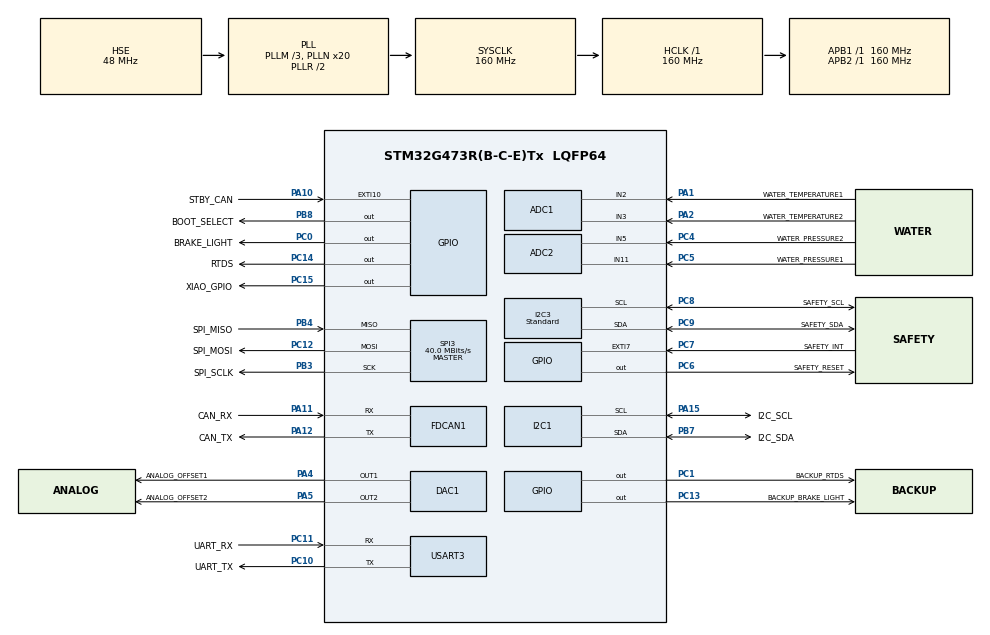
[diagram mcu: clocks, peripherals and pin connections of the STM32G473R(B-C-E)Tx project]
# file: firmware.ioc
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ADC1.Channel-0\#ChannelRegularConversion=ADC_CHANNEL_2
ADC1.Channel-1\#ChannelRegularConversion=ADC_CHANNEL_3
ADC1.Channel-2\#ChannelRegularConversion=ADC_CHANNEL_2
ADC1.Channel-3\#ChannelRegularConversion=ADC_CHANNEL_3
ADC1.Channel-4\#ChannelRegularConversion=ADC_CHANNEL_2
ADC1.Channel-5\#ChannelRegularConversion=ADC_CHANNEL_2
ADC1.ClockPrescaler=ADC_CLOCK_ASYNC_DIV128
ADC1.ContinuousConvMode=ENABLE
ADC1.DMAContinuousRequests=ENABLE
ADC1.EOCSelection=ADC_EOC_SEQ_CONV
ADC1.NbrOfConversion=6
ADC1.NbrOfConversionFlag=1
ADC1.OffsetNumber-0\#ChannelRegularConversion=ADC_OFFSET_NONE
ADC1.OffsetNumber-1\#ChannelRegularConversion=ADC_OFFSET_NONE
ADC1.OffsetNumber-2\#ChannelRegularConversion=ADC_OFFSET_NONE
ADC1.OffsetNumber-3\#ChannelRegularConversion=ADC_OFFSET_NONE
ADC1.OffsetNumber-4\#ChannelRegularConversion=ADC_OFFSET_NONE
ADC1.OffsetNumber-5\#ChannelRegularConversion=ADC_OFFSET_NONE
ADC1.Overrun=ADC_OVR_DATA_OVERWRITTEN
ADC1.Rank-0\#ChannelRegularConversion=1
ADC1.Rank-1\#ChannelRegularConversion=2
ADC1.Rank-2\#ChannelRegularConversion=3
ADC1.Rank-3\#ChannelRegularConversion=4
ADC1.Rank-4\#ChannelRegularConversion=5
ADC1.Rank-5\#ChannelRegularConversion=6
ADC1.SamplingTime-0\#ChannelRegularConversion=ADC_SAMPLETIME_12CYCLES_5
ADC1.SamplingTime-1\#ChannelRegularConversion=ADC_SAMPLETIME_12CYCLES_5
ADC1.SamplingTime-2\#ChannelRegularConversion=ADC_SAMPLETIME_12CYCLES_5
ADC1.SamplingTime-3\#ChannelRegularConversion=ADC_SAMPLETIME_12CYCLES_5
ADC1.SamplingTime-4\#ChannelRegularConversion=ADC_SAMPLETIME_12CYCLES_5
ADC1.SamplingTime-5\#ChannelRegularConversion=ADC_SAMPLETIME_12CYCLES_5
ADC1.master=1
ADC2.Channel-0\#ChannelRegularConversion=ADC_CHANNEL_5
ADC2.Channel-1\#ChannelRegularConversion=ADC_CHANNEL_11
ADC2.Channel-2\#ChannelRegularConversion=ADC_CHANNEL_5
ADC2.Channel-3\#ChannelRegularConversion=ADC_CHANNEL_11
ADC2.ClockPrescaler=ADC_CLOCK_ASYNC_DIV128
ADC2.ContinuousConvMode=ENABLE
ADC2.DMAContinuousRequests=ENABLE
ADC2.EOCSelection=ADC_EOC_SEQ_CONV
ADC2.NbrOfConversion=4
ADC2.NbrOfConversionFlag=1
ADC2.OffsetNumber-0\#ChannelRegularConversion=ADC_OFFSET_NONE
ADC2.OffsetNumber-1\#ChannelRegularConversion=ADC_OFFSET_NONE
ADC2.OffsetNumber-2\#ChannelRegularConversion=ADC_OFFSET_NONE
ADC2.OffsetNumber-3\#ChannelRegularConversion=ADC_OFFSET_NONE
ADC2.Overrun=ADC_OVR_DATA_OVERWRITTEN
ADC2.Rank-0\#ChannelRegularConversion=1
ADC2.Rank-1\#ChannelRegularConversion=2
ADC2.Rank-2\#ChannelRegularConversion=3
ADC2.Rank-3\#ChannelRegularConversion=4
ADC2.SamplingTime-0\#ChannelRegularConversion=ADC_SAMPLETIME_2CYCLES_5
ADC2.SamplingTime-1\#ChannelRegularConversion=ADC_SAMPLETIME_2CYCLES_5
ADC2.SamplingTime-2\#ChannelRegularConversion=ADC_SAMPLETIME_2CYCLES_5
ADC2.SamplingTime-3\#ChannelRegularConversion=ADC_SAMPLETIME_2CYCLES_5
DAC1.DAC_Channel-DAC_OUT2=DAC_CHANNEL_2
Dma.ADC1.0.Direction=DMA_PERIPH_TO_MEMORY
Dma.ADC1.0.EventEnable=DISABLE
Dma.ADC1.0.Instance=DMA1_Channel1
Dma.ADC1.0.MemDataAlignment=DMA_MDATAALIGN_HALFWORD
Dma.ADC1.0.MemInc=DMA_MINC_ENABLE
Dma.ADC1.0.Mode=DMA_CIRCULAR
Dma.ADC1.0.PeriphDataAlignment=DMA_PDATAALIGN_HALFWORD
Dma.ADC1.0.PeriphInc=DMA_PINC_DISABLE
Dma.ADC1.0.Polarity=HAL_DMAMUX_REQ_GEN_RISING
Dma.ADC1.0.Priority=DMA_PRIORITY_LOW
Dma.ADC1.0.RequestNumber=1
Dma.ADC1.0.SignalID=NONE
Dma.ADC1.0.SyncEnable=DISABLE
Dma.ADC1.0.SyncPolarity=HAL_DMAMUX_SYNC_NO_EVENT
Dma.ADC1.0.SyncRequestNumber=1
Dma.ADC1.0.SyncSignalID=NONE
Dma.ADC2.1.Direction=DMA_PERIPH_TO_MEMORY
Dma.ADC2.1.EventEnable=DISABLE
Dma.ADC2.1.Instance=DMA2_Channel2
Dma.ADC2.1.MemDataAlignment=DMA_MDATAALIGN_HALFWORD
Dma.ADC2.1.MemInc=DMA_MINC_ENABLE
Dma.ADC2.1.Mode=DMA_CIRCULAR
Dma.ADC2.1.PeriphDataAlignment=DMA_PDATAALIGN_HALFWORD
Dma.ADC2.1.PeriphInc=DMA_PINC_DISABLE
Dma.ADC2.1.Polarity=HAL_DMAMUX_REQ_GEN_RISING
Dma.ADC2.1.Priority=DMA_PRIORITY_LOW
Dma.ADC2.1.RequestNumber=1
Dma.ADC2.1.SignalID=NONE
Dma.ADC2.1.SyncEnable=DISABLE
Dma.ADC2.1.SyncPolarity=HAL_DMAMUX_SYNC_NO_EVENT
Dma.ADC2.1.SyncRequestNumber=1
Dma.ADC2.1.SyncSignalID=NONE
Dma.Request0=ADC1
Dma.Request1=ADC2
Dma.Request2=USART3_TX
Dma.USART3_TX.2.Direction=DMA_MEMORY_TO_PERIPH
Dma.USART3_TX.2.EventEnable=DISABLE
Dma.USART3_TX.2.Instance=DMA1_Channel2
Dma.USART3_TX.2.MemDataAlignment=DMA_MDATAALIGN_BYTE
Dma.USART3_TX.2.MemInc=DMA_MINC_ENABLE
Dma.USART3_TX.2.Mode=DMA_NORMAL
Dma.USART3_TX.2.PeriphDataAlignment=DMA_PDATAALIGN_BYTE
Dma.USART3_TX.2.PeriphInc=DMA_PINC_DISABLE
Dma.USART3_TX.2.Polarity=HAL_DMAMUX_REQ_GEN_RISING
Dma.USART3_TX.2.Priority=DMA_PRIORITY_LOW
Dma.USART3_TX.2.RequestNumber=1
Dma.USART3_TX.2.SignalID=NONE
Dma.USART3_TX.2.SyncEnable=DISABLE
Dma.USART3_TX.2.SyncPolarity=HAL_DMAMUX_SYNC_NO_EVENT
Dma.USART3_TX.2.SyncRequestNumber=1
Dma.USART3_TX.2.SyncSignalID=NONE
FDCAN1.CalculateBaudRateNominal=1000000
FDCAN1.CalculateTimeBitNominal=1000
FDCAN1.CalculateTimeQuantumNominal=62.5
FDCAN1.DataPrescaler=1
FDCAN1.DataSyncJumpWidth=2
FDCAN1.FrameFormat=FDCAN_FRAME_CLASSIC
FDCAN1.NominalPrescaler=10
FDCAN1.NominalSyncJumpWidth=2
FDCAN1.NominalTimeSeg1=13
FDCAN1.NominalTimeSeg2=2
FDCAN1.StdFiltersNbr=1
FREERTOS.Mutexes01=dataMutex,Dynamic,NULL;safetyMutex,Dynamic,NULL
FREERTOS.Tasks01=defaultTask,24,128,Default_Task,Default,NULL,Dynamic,NULL,NULL;interfaceTask,24,256,Interface_Task,As external,NULL,Dynamic,NULL,NULL;communicationTask,24,256,Communication_Task,As external,NULL,Dynamic,NULL,NULL;safetyTask,32,256,Safety_Task,As external,NULL,Dynamic,NULL,NULL;ledTestTask,8,128,Led_Test_Task,As external,NULL,Dynamic,NULL,NULL
FREERTOS.configMAX_TASK_NAME_LEN=24
FREERTOS.configTOTAL_HEAP_SIZE=16384
FREERTOS.configUSE_NEWLIB_REENTRANT=1
I2C1.Timing=0x30D29DE4
I2C3.I2C_Fall_Time=300
I2C3.I2C_Rise_Time=1000
I2C3.I2C_Speed_Mode=I2C_Standard
I2C3.Timing=0xD0E32C34
Mcu.Family=STM32G4
Mcu.Name=STM32G473R(B-C-E)Tx
Mcu.Package=LQFP64
NVIC.DMA1_Channel1_IRQn=true\:5\:0\:true\:false\:true\:true\:false\:true\:true
NVIC.DMA1_Channel2_IRQn=true\:5\:0\:false\:false\:true\:true\:false\:true\:true
NVIC.DMA2_Channel2_IRQn=true\:5\:0\:true\:false\:true\:true\:false\:true\:true
NVIC.FDCAN1_IT0_IRQn=true\:5\:0\:false\:false\:true\:true\:true\:true\:true
NVIC.FDCAN1_IT1_IRQn=true\:5\:0\:false\:false\:true\:true\:true\:true\:true
NVIC.PriorityGroup=NVIC_PRIORITYGROUP_4
NVIC.TIM6_DAC_IRQn=true\:15\:0\:false\:false\:true\:false\:false\:true\:true
NVIC.TimeBase=TIM6_DAC_IRQn
NVIC.TimeBaseIP=TIM6
PA1.GPIO_Label=WATER_TEMPERATURE1
PA1.GPIO_Mode=GPIO_MODE_ANALOG
PA1.Mode=IN2-Single-Ended
PA1.Signal=ADC1_IN2
PA10.GPIO_Label=STBY_CAN
PA10.Signal=GPXTI10
PA11.GPIO_Label=CAN_RX
PA11.Mode=FDCAN_Activate
PA11.Signal=FDCAN1_RX
PA12.GPIO_Label=CAN_TX
PA12.Mode=FDCAN_Activate
PA12.Signal=FDCAN1_TX
PA13.GPIO_Label=SWDIO
PA13.Mode=Serial_Wire
PA13.Signal=SYS_JTMS-SWDIO
PA14.GPIO_Label=SWCLK
PA14.Mode=Serial_Wire
PA14.Signal=SYS_JTCK-SWCLK
PA15.GPIO_Label=I2C_SCL
PA15.Mode=I2C
PA15.Signal=I2C1_SCL
PA2.GPIO_Label=WATER_TEMPERATURE2
PA2.Mode=IN3-Single-Ended
PA2.Signal=ADC1_IN3
PA4.GPIO_Label=ANALOG_OFFSET1
PA4.Signal=COMP_DAC11_group
PA5.GPIO_Label=ANALOG_OFFSET2
PA5.Signal=COMP_DAC12_group
PB3.GPIO_Label=SPI_SCLK
PB3.Mode=Full_Duplex_Master
PB3.Signal=SPI3_SCK
PB4.GPIO_Label=SPI_MISO
PB4.Mode=Full_Duplex_Master
PB4.Signal=SPI3_MISO
PB7.GPIO_Label=I2C_SDA
PB7.Mode=I2C
PB7.Signal=I2C1_SDA
PB8-BOOT0.GPIO_Label=BOOT_SELECT
PB8-BOOT0.Signal=GPIO_Output
PC0.GPIO_Label=BRAKE_LIGHT
PC0.Signal=GPIO_Output
PC1.GPIO_Label=BACKUP_RTDS
PC1.Signal=GPIO_Output
PC10.GPIO_Label=UART_TX
PC10.Mode=Asynchronous
PC10.Signal=USART3_TX
PC11.GPIO_Label=UART_RX
PC11.Mode=Asynchronous
PC11.Signal=USART3_RX
PC12.GPIO_Label=SPI_MOSI
PC12.Mode=Full_Duplex_Master
PC12.Signal=SPI3_MOSI
PC13.GPIO_Label=BACKUP_BRAKE_LIGHT
PC13.Signal=GPIO_Output
PC14-OSC32_IN.GPIO_Label=RTDS
PC14-OSC32_IN.Signal=GPIO_Output
PC15-OSC32_OUT.GPIO_Label=XIAO_GPIO
PC15-OSC32_OUT.Signal=GPIO_Output
PC4.GPIO_Label=WATER_PRESSURE2
PC4.Mode=IN5-Single-Ended
PC4.Signal=ADC2_IN5
PC5.GPIO_Label=WATER_PRESSURE1
PC5.Mode=IN11-Single-Ended
PC5.Signal=ADC2_IN11
PC6.GPIO_Label=SAFETY_RESET
PC6.GPIO_PuPd=GPIO_PULLUP
PC6.PinState=GPIO_PIN_SET
PC6.Signal=GPIO_Output
PC7.GPIO_Label=SAFETY_INT
PC7.GPIO_ModeDefaultEXTI=GPIO_MODE_IT_FALLING
PC7.GPIO_PuPd=GPIO_PULLUP
PC7.Signal=GPXTI7
PC8.GPIO_Label=SAFETY_SCL
PC8.GPIO_Pu=GPIO_PULLUP
PC8.Mode=I2C
PC8.Signal=I2C3_SCL
PC9.GPIO_Label=SAFETY_SDA
PC9.GPIO_Pu=GPIO_PULLUP
PC9.Mode=I2C
PC9.Signal=I2C3_SDA
PF0-OSC_IN.GPIO_Label=HSE_IN
PF0-OSC_IN.Mode=HSE-External-Oscillator
PF0-OSC_IN.Signal=RCC_OSC_IN
PF1-OSC_OUT.GPIO_Label=HSE_OUT
PF1-OSC_OUT.Mode=HSE-External-Oscillator
PF1-OSC_OUT.Signal=RCC_OSC_OUT
ProjectManager.HeapSize=0x200
ProjectManager.StackSize=0x400
ProjectManager.TargetToolchain=CMake
RCC.ADC12Freq_Value=160000000
RCC.ADC345Freq_Value=160000000
RCC.AHBFreq_Value=160000000
RCC.APB1Freq_Value=160000000
RCC.APB1TimFreq_Value=160000000
RCC.APB2Freq_Value=160000000
RCC.APB2TimFreq_Value=160000000
RCC.CK48CLockSelection=RCC_USBCLKSOURCE_HSI48
RCC.CortexFreq_Value=160000000
RCC.EXTERNAL_CLOCK_VALUE=12288000
RCC.HCLKFreq_Value=160000000
RCC.HSE_VALUE=48000000
RCC.HSI48_VALUE=48000000
RCC.HSI_VALUE=16000000
RCC.LSE_VALUE=32768
RCC.PLLM=RCC_PLLM_DIV3
RCC.PLLN=20
RCC.PLLQ=RCC_PLLQ_DIV8
RCC.PLLSourceVirtual=RCC_PLLSOURCE_HSE
RCC.SYSCLKFreq_VALUE=160000000
RCC.SYSCLKSource=RCC_SYSCLKSOURCE_PLLCLK
RCC.USBFreq_Value=48000000
RCC.VCOOutputFreq_Value=320000000
SH.COMP_DAC11_group.0=DAC1_OUT1,DAC_OUT1
SH.COMP_DAC12_group.0=DAC1_OUT2,DAC_OUT2
SPI3.BaudRatePrescaler=SPI_BAUDRATEPRESCALER_4
SPI3.CalculateBaudRate=40.0 MBits/s
SPI3.Direction=SPI_DIRECTION_2LINES
SPI3.Mode=SPI_MODE_MASTER
SPI3.VirtualType=VM_MASTER
USART3.SwapParam=ADVFEATURE_SWAP_ENABLE
USART3.VirtualMode-Asynchronous=VM_ASYNC
VP_FREERTOS_VS_CMSIS_V2.Mode=CMSIS_V2
VP_SYS_VS_DBSignals.Mode=DisableDeadBatterySignals
VP_SYS_VS_tim6.Mode=TIM6
board=custom

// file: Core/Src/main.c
/* USER CODE BEGIN Header */
/**
  ******************************************************************************
  * @file           : main.c
  * @brief          : Main program body
  ******************************************************************************
  * @attention
  *
  * Copyright (c) 2026 STMicroelectronics.
  * All rights reserved.
  *
  * This software is licensed under terms that can be found in the LICENSE file
  * in the root directory of this software component.
  * If no LICENSE file comes with this software, it is provided AS-IS.
  *
  ******************************************************************************
  */
/* USER CODE END Header */
#include "main.h"
#include "cmsis_os.h"
#include "adc.h"
#include "dac.h"
#include "dma.h"
#include "fdcan.h"
#include "i2c.h"
#include "spi.h"
#include "usart.h"
#include "gpio.h"

void SystemClock_Config(void);
void MX_FREERTOS_Init(void);

int main(void)
{

  /* MCU Configuration--------------------------------------------------------*/

  /* Reset of all peripherals, Initializes the Flash interface and the Systick. */
  HAL_Init();

  /* Configure the system clock */
  SystemClock_Config();

  /* Initialize all configured peripherals */
  MX_GPIO_Init();
  MX_DMA_Init();
  MX_FDCAN1_Init();
  MX_I2C3_Init();
  MX_USART3_UART_Init();
  MX_DAC1_Init();
  MX_SPI3_Init();
  MX_ADC1_Init();
  MX_ADC2_Init();
  MX_I2C1_Init();

  /* Init scheduler */
  osKernelInitialize();  /* Call init function for freertos objects (in cmsis_os2.c) */
  MX_FREERTOS_Init();

  /* Start scheduler */
  osKernelStart();

  /* We should never get here as control is now taken by the scheduler */

  /* Infinite loop */
  while (1)
  {

  }
}

void SystemClock_Config(void)
{
  RCC_OscInitTypeDef RCC_OscInitStruct = {0};
  RCC_ClkInitTypeDef RCC_ClkInitStruct = {0};

  /** Configure the main internal regulator output voltage
  */
  HAL_PWREx_ControlVoltageScaling(PWR_REGULATOR_VOLTAGE_SCALE1_BOOST);

  /** Initializes the RCC Oscillators according to the specified parameters
  * in the RCC_OscInitTypeDef structure.
  */
  RCC_OscInitStruct.OscillatorType = RCC_OSCILLATORTYPE_HSE;
  RCC_OscInitStruct.HSEState = RCC_HSE_ON;
  RCC_OscInitStruct.PLL.PLLState = RCC_PLL_ON;
  RCC_OscInitStruct.PLL.PLLSource = RCC_PLLSOURCE_HSE;
  RCC_OscInitStruct.PLL.PLLM = RCC_PLLM_DIV3;
  RCC_OscInitStruct.PLL.PLLN = 20;
  RCC_OscInitStruct.PLL.PLLP = RCC_PLLP_DIV2;
  RCC_OscInitStruct.PLL.PLLQ = RCC_PLLQ_DIV8;
  RCC_OscInitStruct.PLL.PLLR = RCC_PLLR_DIV2;
  if (HAL_RCC_OscConfig(&RCC_OscInitStruct) != HAL_OK)
  {
    Error_Handler();
  }

  /** Initializes the CPU, AHB and APB buses clocks
  */
  RCC_ClkInitStruct.ClockType = RCC_CLOCKTYPE_HCLK|RCC_CLOCKTYPE_SYSCLK
                              |RCC_CLOCKTYPE_PCLK1|RCC_CLOCKTYPE_PCLK2;
  RCC_ClkInitStruct.SYSCLKSource = RCC_SYSCLKSOURCE_PLLCLK;
  RCC_ClkInitStruct.AHBCLKDivider = RCC_SYSCLK_DIV1;
  RCC_ClkInitStruct.APB1CLKDivider = RCC_HCLK_DIV1;
  RCC_ClkInitStruct.APB2CLKDivider = RCC_HCLK_DIV1;

  if (HAL_RCC_ClockConfig(&RCC_ClkInitStruct, FLASH_LATENCY_4) != HAL_OK)
  {
    Error_Handler();
  }
}

void HAL_TIM_PeriodElapsedCallback(TIM_HandleTypeDef *htim)
{
  if (htim->Instance == TIM6)
  {
    HAL_IncTick();
  }
}

void Error_Handler(void)
{
  __disable_irq();
  while (1)
  {
  }
}

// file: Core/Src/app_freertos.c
/* USER CODE BEGIN Header */
/**
 ******************************************************************************
 * File Name          : app_freertos.c
 * Description        : Code for freertos applications
 ******************************************************************************
 * @attention
 *
 * Copyright (c) 2024 STMicroelectronics.
 * All rights reserved.
 *
 * This software is licensed under terms that can be found in the LICENSE file
 * in the root directory of this software component.
 * If no LICENSE file comes with this software, it is provided AS-IS.
 *
 ******************************************************************************
 */
/* USER CODE END Header */

#include "FreeRTOS.h"
#include "task.h"
#include "main.h"
#include "cmsis_os.h"

/* USER CODE BEGIN Includes */
#include "communication_task.h"
#include "interface_task.h"
#include "led_test_task.h"
#include "safety_task.h"
/* USER CODE END Includes */

/* USER CODE BEGIN Variables */
osSemaphoreId_t uartTxSemHandle;
/* USER CODE END Variables */
/* Definitions for defaultTask */
osThreadId_t defaultTaskHandle;
const osThreadAttr_t defaultTask_attributes = {
  .name = "defaultTask",
  .priority = (osPriority_t) osPriorityNormal,
  .stack_size = 128 * 4
};
/* Definitions for interfaceTask */
osThreadId_t interfaceTaskHandle;
const osThreadAttr_t interfaceTask_attributes = {
  .name = "interfaceTask",
  .priority = (osPriority_t) osPriorityNormal,
  .stack_size = 256 * 4
};
/* Definitions for communicationTask */
osThreadId_t communicationTaskHandle;
const osThreadAttr_t communicationTask_attributes = {
  .name = "communicationTask",
  .priority = (osPriority_t) osPriorityNormal,
  .stack_size = 256 * 4
};
/* Definitions for safetyTask */
osThreadId_t safetyTaskHandle;
const osThreadAttr_t safetyTask_attributes = {
  .name = "safetyTask",
  .priority = (osPriority_t) osPriorityAboveNormal,
  .stack_size = 256 * 4
};
/* Definitions for ledTestTask */
osThreadId_t ledTestTaskHandle;
const osThreadAttr_t ledTestTask_attributes = {
  .name = "ledTestTask",
  .priority = (osPriority_t) osPriorityLow,
  .stack_size = 128 * 4
};
/* Definitions for dataMutex */
osMutexId_t dataMutexHandle;
const osMutexAttr_t dataMutex_attributes = {
  .name = "dataMutex"
};
/* Definitions for safetyMutex */
osMutexId_t safetyMutexHandle;
const osMutexAttr_t safetyMutex_attributes = {
  .name = "safetyMutex"
};

void Default_Task(void *argument);
extern void Interface_Task(void *argument);
extern void Communication_Task(void *argument);
extern void Safety_Task(void *argument);
extern void Led_Test_Task(void *argument);

void MX_FREERTOS_Init(void); /* (MISRA C 2004 rule 8.1) */

void MX_FREERTOS_Init(void) {
  /* Create the mutex(es) */
  /* creation of dataMutex */
  dataMutexHandle = osMutexNew(&dataMutex_attributes);

  /* creation of safetyMutex */
  safetyMutexHandle = osMutexNew(&safetyMutex_attributes);

  /* USER CODE BEGIN RTOS_SEMAPHORES */
  uartTxSemHandle = osSemaphoreNew(1, 1, NULL);
  /* USER CODE END RTOS_SEMAPHORES */

  /* Create the thread(s) */
  /* creation of defaultTask */
  defaultTaskHandle = osThreadNew(Default_Task, NULL, &defaultTask_attributes);

  /* creation of interfaceTask */
  interfaceTaskHandle = osThreadNew(Interface_Task, NULL, &interfaceTask_attributes);

  /* creation of communicationTask */
  communicationTaskHandle = osThreadNew(Communication_Task, NULL, &communicationTask_attributes);

  /* creation of safetyTask */
  safetyTaskHandle = osThreadNew(Safety_Task, NULL, &safetyTask_attributes);

  /* creation of ledTestTask */
  ledTestTaskHandle = osThreadNew(Led_Test_Task, NULL, &ledTestTask_attributes);

}

void Default_Task(void *argument)
{
  /* USER CODE BEGIN Default_Task */
    /* Infinite loop */
    for(;;) {
        vTaskDelay(1);
    }
  /* USER CODE END Default_Task */
}
